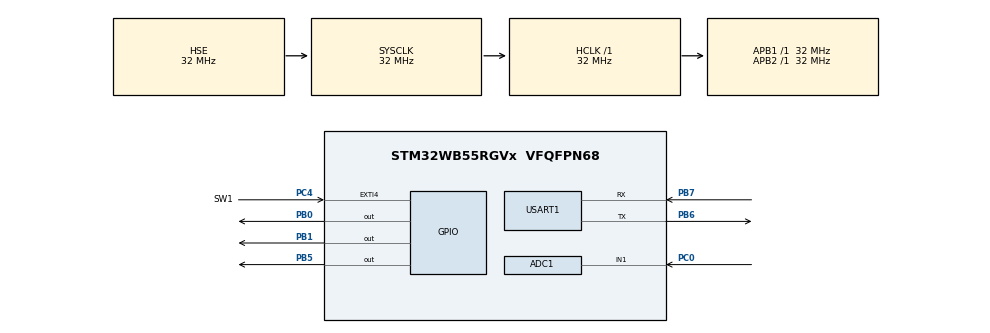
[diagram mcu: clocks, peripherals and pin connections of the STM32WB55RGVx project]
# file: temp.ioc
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Mcu.Family=STM32WB
STM32_WPAN.GAP_PERIPHERAL_ROLE=1
RCC.CortexFreq_Value=32000000
STM32_WPAN.SERVICE2_UUID_TYPE=0x01
STM32_WPAN.SERVICE1_CHAR1_GATT_NOTIFY_ATTRIBUTE_WRITE=\ 
RF1.Signal=RF_RF1
Dma.USART1_TX.0.RequestNumber=1
STM32_WPAN.SERVICE2_TYPE=PRIMARY_SERVICE
Dma.USART1_TX.0.SignalID=NONE
STM32_WPAN.CUSTOM_TEMPLATE=Enabled
VP_RTC_VS_RTC_Activate.Mode=RTC_Enabled
RCC.SYSCLKSource=RCC_SYSCLKSOURCE_HSE
ProjectManager.StackSize=0x400
STM32_WPAN.AD_SERVICE_CLASS_UUID_NBR=2
STM32_WPAN.INCLUDE_AD_TYPE_16_BIT_SERV_UUID_CMPLT_LIST=1
STM32_WPAN.SERVICE2_SHORT_NAME=eserv
STM32_WPAN.SERVICE2_CHAR1_GATT_NOTIFY_WRITE_REQ_AND_WAIT_FOR_APPL_RESP=\ 
Dma.USART1_TX.0.Priority=DMA_PRIORITY_LOW
STM32_WPAN.SERVICE2_CHAR1_UUID=2A 37
STM32_WPAN.NUMBER_OF_SERVICES=2
Dma.USART1_TX.0.Direction=DMA_MEMORY_TO_PERIPH
Dma.USART1_TX.0.SyncPolarity=HAL_DMAMUX_SYNC_NO_EVENT
STM32_WPAN.SERVICE1_UUID_TYPE=0x01
STM32_WPAN.SERVICE2_CHAR1_UUID_TYPE=0x01
RCC.HCLKFreq_Value=32000000
STM32_WPAN.LOCAL_NAME=ABC123
RCC.APB2TimFreq_Value=32000000
PB6.Signal=USART1_TX
PB6.Mode=Asynchronous
OSC_OUT.Mode=HSE-External-Oscillator
STM32_WPAN.SERVICE1_CHAR1_PROP_READ=CHAR_PROP_READ
OSC_OUT.Signal=RCC_OSC_OUT
RCC.AHBFreq_Value=32000000
ADC1.Channel-0\#ChannelRegularConversion=ADC_CHANNEL_1
RCC.HSE_VALUE=32000000
RCC.RTCClockSelection=RCC_RTCCLKSOURCE_LSE
STM32_WPAN.SERVICE1_CHAR1_UUID=2A 19
STM32_WPAN.SERVICE1_UUID=18 0F
PC14-OSC32_IN.Mode=LSE-External-Oscillator
PC4.GPIO_Label=SW1
STM32_WPAN.SERVICE1_SHORT_NAME=bserv
NVIC.DMA2_Channel4_IRQn=true\:0\:0\:false\:false\:true\:false\:true
Dma.USART1_TX.0.SyncRequestNumber=1
STM32_WPAN.SERVICE2_UUID=18 0D
PB7.Signal=USART1_RX
STM32_WPAN.INCLUDE_AD_TYPE_SHORTENED_LOCAL_NAME=1
Dma.USART1_TX.0.PeriphDataAlignment=DMA_PDATAALIGN_BYTE
STM32_WPAN.SERVICE2_LONG_NAME=eeg_service
ADC1.SamplingTime-0\#ChannelRegularConversion=ADC_SAMPLETIME_2CYCLES_5
RCC.APB3Freq_Value=16000000
NVIC.HSEM_IRQn=true\:0\:0\:false\:false\:true\:false\:true
Mcu.Package=VFQFPN68
PB1.Signal=GPIO_Output
STM32_WPAN.SERVICE2_CHAR1_LONG_NAME=eeg_value
Dma.USART1_TX.0.Instance=DMA2_Channel4
VP_TINY_LPM_VS_TINY_LPM.Mode=TINY_LPM_Enabled
SH.ADCx_IN1.0=ADC1_IN1,IN1-Single-Ended
VP_HSEM_VS_HSEM.Mode=HSEM_Activate
STM32_WPAN.CFG_GAP_DEVICE_NAME=DEABrain
RCC.APB1TimFreq_Value=32000000
Dma.USART1_TX.0.EventEnable=DISABLE
STM32_WPAN.SERVICE1_CHAR1_UUID_TYPE=0x01
Dma.Request0=USART1_TX
RCC.HSI48_VALUE=48000000
RCC.PLLSAI1N=24
Dma.USART1_TX.0.SyncSignalID=NONE
PC15-OSC32_OUT.Mode=LSE-External-Oscillator
NVIC.EXTI4_IRQn=true\:0\:0\:false\:false\:true\:true\:true
STM32_WPAN.SERVICE1_TYPE=PRIMARY_SERVICE
Dma.USART1_TX.0.MemInc=DMA_MINC_ENABLE
ADC1.Rank-0\#ChannelRegularConversion=1
Dma.USART1_TX.0.PeriphInc=DMA_PINC_DISABLE
VP_STM32_WPAN_VS_BLE_HOST.Mode=STM32_WPAN_Enabled
PC4.GPIO_PuPd=GPIO_PULLUP
ADC1.OffsetNumber-0\#ChannelRegularConversion=ADC_OFFSET_NONE
STM32_WPAN.AD_SERVICE_CLASS_UUID_1_INV=[0F, 18]
PC4.Signal=GPXTI4
Dma.USART1_TX.0.Polarity=HAL_DMAMUX_REQ_GEN_RISING
STM32_WPAN.SERVICE1_CHAR1_GATT_NOTIFY_WRITE_REQ_AND_WAIT_FOR_APPL_RESP=\ 
PC0.Signal=ADCx_IN1
PC14-OSC32_IN.Signal=RCC_OSC32_IN
STM32_WPAN.SERVICE2_CHAR1_PROP_READ=CHAR_PROP_READ
STM32_WPAN.SERVICE2_CHAR1_PROP_NOTIFY=CHAR_PROP_NOTIFY
STM32_WPAN.AD_SERVICE_CLASS_UUID_2=18 0D
STM32_WPAN.AD_SERVICE_CLASS_UUID_1=18 0F
USART1.VirtualMode-Asynchronous=VM_ASYNC
STM32_WPAN.SERVICE1_CHAR1_PROP_NOTIFY=CHAR_PROP_NOTIFY
ProjectManager.TargetToolchain=STM32CubeIDE
STM32_WPAN.LOCAL_NAME_FORMATTED=,'A','B','C','1','2','3'
Dma.USART1_TX.0.SyncEnable=DISABLE
STM32_WPAN.CUSTOM_P2P_SERVER=Disabled
OSC_IN.Signal=RCC_OSC_IN
RCC.USBFreq_Value=48000000
STM32_WPAN.SERVICE2_CHAR1_SHORT_NAME=val
PC15-OSC32_OUT.Signal=RCC_OSC32_OUT
RCC.SMPSCLockSelectionVirtual=RCC_SMPSCLKSOURCE_HSE
STM32_WPAN.SERVICE1_LONG_NAME=battery_service
Dma.USART1_TX.0.Mode=DMA_NORMAL
board=custom
STM32_WPAN.SERVICE1_CHAR1_GATT_NOTIFY_READ_REQ_AND_WAIT_FOR_APPL_RESP=\ 
VP_SEQUENCER_VS_SEQUENCER.Mode=SEQUENCER_Enabled
RCC.VCOOutputFreq_Value=32000000
STM32_WPAN.SERVICE2_CHAR1_VALUE_LENGTH=2
RCC.APB2Freq_Value=32000000
STM32_WPAN.AD_SERVICE_CLASS_UUID_2_INV=[0D, 18]
STM32_WPAN.CFG_BONDING_MODE=1
RCC.ADCFreq_Value=48000000
STM32_WPAN.SERVICE2_CHAR1_GATT_NOTIFY_READ_REQ_AND_WAIT_FOR_APPL_RESP=\ 
Mcu.Name=STM32WB55RGVx
STM32_WPAN.SERVICE1_CHAR1_SHORT_NAME=bval
RCC.SYSCLKFreq_VALUE=32000000
PB5.Signal=GPIO_Output
ADC1.master=1
OSC_IN.Mode=HSE-External-Oscillator
STM32_WPAN.SERVICE1_CHAR1_VALUE_LENGTH=2
RF1.Mode=RF1_Activate
PB7.Mode=Asynchronous
Dma.USART1_TX.0.MemDataAlignment=DMA_MDATAALIGN_BYTE
ProjectManager.HeapSize=0x200
RCC.HSI_VALUE=16000000
NVIC.PriorityGroup=NVIC_PRIORITYGROUP_4
ADC1.NbrOfConversionFlag=1
STM32_WPAN.SERVICE1_CHAR1_LONG_NAME=battery_value
RCC.APB1Freq_Value=32000000
RCC.RFWKPClockSelection=RCC_RFWKPCLKSOURCE_LSE
PB0.Signal=GPIO_Output
STM32_WPAN.SERVICE2_CHAR1_GATT_NOTIFY_ATTRIBUTE_WRITE=\ 

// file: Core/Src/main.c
/* USER CODE BEGIN Header */
/**
  ******************************************************************************
  * @file           : main.c
  * @brief          : Main program body
  ******************************************************************************
  * @attention
  *
  * <h2><center>&copy; Copyright (c) 2021 STMicroelectronics.
  * All rights reserved.</center></h2>
  *
  * This software component is licensed by ST under BSD 3-Clause license,
  * the "License"; You may not use this file except in compliance with the
  * License. You may obtain a copy of the License at:
  *                        opensource.org/licenses/BSD-3-Clause
  *
  ******************************************************************************
  */
/* USER CODE END Header */
#include "main.h"

/* USER CODE BEGIN Includes */
#include "stm32_seq.h"
/* USER CODE END Includes */

ADC_HandleTypeDef hadc1;

RTC_HandleTypeDef hrtc;

UART_HandleTypeDef huart1;
DMA_HandleTypeDef hdma_usart1_tx;

void SystemClock_Config(void);
static void MX_GPIO_Init(void);
static void MX_DMA_Init(void);
static void MX_RF_Init(void);
static void MX_RTC_Init(void);
static void MX_ADC1_Init(void);
static void MX_USART1_UART_Init(void);

int main(void)
{

  /* MCU Configuration--------------------------------------------------------*/

  /* Reset of all peripherals, Initializes the Flash interface and the Systick. */
  HAL_Init();

  /* Configure the system clock */
  SystemClock_Config();

  /* Initialize all configured peripherals */
  MX_GPIO_Init();
  MX_DMA_Init();
  MX_RF_Init();
  MX_RTC_Init();
  MX_ADC1_Init();
  MX_USART1_UART_Init();
  /* USER CODE BEGIN 2 */
  uint8_t str[] = "Hello World!\r\n";
  HAL_UART_Transmit_DMA(&huart1, str, sizeof(str));

  /* USER CODE END 2 */

  /* Init code for STM32_WPAN */
  APPE_Init();
  /* Infinite loop */
  /* USER CODE BEGIN WHILE */
  while (1)
  {
	  UTIL_SEQ_Run( UTIL_SEQ_DEFAULT );
//	  HAL_GPIO_WritePin(GPIOB, GPIO_PIN_5,GPIO_PIN_SET);
//	  HAL_GPIO_TogglePin(GPIOB, GPIO_PIN_5);
//	  HAL_Delay(100);
    /* USER CODE END WHILE */

  }
}

void SystemClock_Config(void)
{
  RCC_OscInitTypeDef RCC_OscInitStruct = {0};
  RCC_ClkInitTypeDef RCC_ClkInitStruct = {0};
  RCC_PeriphCLKInitTypeDef PeriphClkInitStruct = {0};

  /** Macro to configure the PLL multiplication factor
  */
  __HAL_RCC_PLL_PLLM_CONFIG(RCC_PLLM_DIV1);
  /** Macro to configure the PLL clock source
  */
  __HAL_RCC_PLL_PLLSOURCE_CONFIG(RCC_PLLSOURCE_MSI);
  /** Configure LSE Drive Capability
  */
  HAL_PWR_EnableBkUpAccess();
  __HAL_RCC_LSEDRIVE_CONFIG(RCC_LSEDRIVE_LOW);
  /** Configure the main internal regulator output voltage
  */
  __HAL_PWR_VOLTAGESCALING_CONFIG(PWR_REGULATOR_VOLTAGE_SCALE1);
  /** Initializes the RCC Oscillators according to the specified parameters
  * in the RCC_OscInitTypeDef structure.
  */
  RCC_OscInitStruct.OscillatorType = RCC_OSCILLATORTYPE_HSI|RCC_OSCILLATORTYPE_HSE
                              |RCC_OSCILLATORTYPE_LSE|RCC_OSCILLATORTYPE_MSI;
  RCC_OscInitStruct.HSEState = RCC_HSE_ON;
  RCC_OscInitStruct.LSEState = RCC_LSE_ON;
  RCC_OscInitStruct.HSIState = RCC_HSI_ON;
  RCC_OscInitStruct.MSIState = RCC_MSI_ON;
  RCC_OscInitStruct.HSICalibrationValue = RCC_HSICALIBRATION_DEFAULT;
  RCC_OscInitStruct.MSICalibrationValue = RCC_MSICALIBRATION_DEFAULT;
  RCC_OscInitStruct.MSIClockRange = RCC_MSIRANGE_6;
  RCC_OscInitStruct.PLL.PLLState = RCC_PLL_NONE;
  if (HAL_RCC_OscConfig(&RCC_OscInitStruct) != HAL_OK)
  {
    Error_Handler();
  }
  /** Configure the SYSCLKSource, HCLK, PCLK1 and PCLK2 clocks dividers
  */
  RCC_ClkInitStruct.ClockType = RCC_CLOCKTYPE_HCLK4|RCC_CLOCKTYPE_HCLK2
                              |RCC_CLOCKTYPE_HCLK|RCC_CLOCKTYPE_SYSCLK
                              |RCC_CLOCKTYPE_PCLK1|RCC_CLOCKTYPE_PCLK2;
  RCC_ClkInitStruct.SYSCLKSource = RCC_SYSCLKSOURCE_HSE;
  RCC_ClkInitStruct.AHBCLKDivider = RCC_SYSCLK_DIV1;
  RCC_ClkInitStruct.APB1CLKDivider = RCC_HCLK_DIV1;
  RCC_ClkInitStruct.APB2CLKDivider = RCC_HCLK_DIV1;
  RCC_ClkInitStruct.AHBCLK2Divider = RCC_SYSCLK_DIV1;
  RCC_ClkInitStruct.AHBCLK4Divider = RCC_SYSCLK_DIV1;

  if (HAL_RCC_ClockConfig(&RCC_ClkInitStruct, FLASH_LATENCY_1) != HAL_OK)
  {
    Error_Handler();
  }
  /** Initializes the peripherals clocks
  */
  PeriphClkInitStruct.PeriphClockSelection = RCC_PERIPHCLK_SMPS|RCC_PERIPHCLK_RFWAKEUP
                              |RCC_PERIPHCLK_RTC|RCC_PERIPHCLK_USART1
                              |RCC_PERIPHCLK_ADC;
  PeriphClkInitStruct.PLLSAI1.PLLN = 24;
  PeriphClkInitStruct.PLLSAI1.PLLP = RCC_PLLP_DIV2;
  PeriphClkInitStruct.PLLSAI1.PLLQ = RCC_PLLQ_DIV2;
  PeriphClkInitStruct.PLLSAI1.PLLR = RCC_PLLR_DIV2;
  PeriphClkInitStruct.PLLSAI1.PLLSAI1ClockOut = RCC_PLLSAI1_ADCCLK;
  PeriphClkInitStruct.Usart1ClockSelection = RCC_USART1CLKSOURCE_PCLK2;
  PeriphClkInitStruct.AdcClockSelection = RCC_ADCCLKSOURCE_PLLSAI1;
  PeriphClkInitStruct.RTCClockSelection = RCC_RTCCLKSOURCE_LSE;
  PeriphClkInitStruct.RFWakeUpClockSelection = RCC_RFWKPCLKSOURCE_LSE;
  PeriphClkInitStruct.SmpsClockSelection = RCC_SMPSCLKSOURCE_HSE;
  PeriphClkInitStruct.SmpsDivSelection = RCC_SMPSCLKDIV_RANGE0;
  if (HAL_RCCEx_PeriphCLKConfig(&PeriphClkInitStruct) != HAL_OK)
  {
    Error_Handler();
  }
}

static void MX_ADC1_Init(void)
{

  ADC_ChannelConfTypeDef sConfig = {0};

  /** Common config
  */
  hadc1.Instance = ADC1;
  hadc1.Init.ClockPrescaler = ADC_CLOCK_ASYNC_DIV1;
  hadc1.Init.Resolution = ADC_RESOLUTION_12B;
  hadc1.Init.DataAlign = ADC_DATAALIGN_RIGHT;
  hadc1.Init.ScanConvMode = ADC_SCAN_DISABLE;
  hadc1.Init.EOCSelection = ADC_EOC_SINGLE_CONV;
  hadc1.Init.LowPowerAutoWait = DISABLE;
  hadc1.Init.ContinuousConvMode = DISABLE;
  hadc1.Init.NbrOfConversion = 1;
  hadc1.Init.DiscontinuousConvMode = DISABLE;
  hadc1.Init.ExternalTrigConv = ADC_SOFTWARE_START;
  hadc1.Init.ExternalTrigConvEdge = ADC_EXTERNALTRIGCONVEDGE_NONE;
  hadc1.Init.DMAContinuousRequests = DISABLE;
  hadc1.Init.Overrun = ADC_OVR_DATA_PRESERVED;
  hadc1.Init.OversamplingMode = DISABLE;
  if (HAL_ADC_Init(&hadc1) != HAL_OK)
  {
    Error_Handler();
  }
  /** Configure Regular Channel
  */
  sConfig.Channel = ADC_CHANNEL_1;
  sConfig.Rank = ADC_REGULAR_RANK_1;
  sConfig.SamplingTime = ADC_SAMPLETIME_2CYCLES_5;
  sConfig.SingleDiff = ADC_SINGLE_ENDED;
  sConfig.OffsetNumber = ADC_OFFSET_NONE;
  sConfig.Offset = 0;
  if (HAL_ADC_ConfigChannel(&hadc1, &sConfig) != HAL_OK)
  {
    Error_Handler();
  }

}

static void MX_RF_Init(void)
{

}

static void MX_RTC_Init(void)
{

  /** Initialize RTC Only
  */
  hrtc.Instance = RTC;
  hrtc.Init.HourFormat = RTC_HOURFORMAT_24;
  hrtc.Init.AsynchPrediv = CFG_RTC_ASYNCH_PRESCALER;
  hrtc.Init.SynchPrediv = CFG_RTC_SYNCH_PRESCALER;
  hrtc.Init.OutPut = RTC_OUTPUT_DISABLE;
  hrtc.Init.OutPutPolarity = RTC_OUTPUT_POLARITY_HIGH;
  hrtc.Init.OutPutType = RTC_OUTPUT_TYPE_OPENDRAIN;
  hrtc.Init.OutPutRemap = RTC_OUTPUT_REMAP_NONE;
  if (HAL_RTC_Init(&hrtc) != HAL_OK)
  {
    Error_Handler();
  }

}

static void MX_USART1_UART_Init(void)
{

  huart1.Instance = USART1;
  huart1.Init.BaudRate = 115200;
  huart1.Init.WordLength = UART_WORDLENGTH_8B;
  huart1.Init.StopBits = UART_STOPBITS_1;
  huart1.Init.Parity = UART_PARITY_NONE;
  huart1.Init.Mode = UART_MODE_TX_RX;
  huart1.Init.HwFlowCtl = UART_HWCONTROL_NONE;
  huart1.Init.OverSampling = UART_OVERSAMPLING_16;
  huart1.Init.OneBitSampling = UART_ONE_BIT_SAMPLE_DISABLE;
  huart1.Init.ClockPrescaler = UART_PRESCALER_DIV1;
  huart1.AdvancedInit.AdvFeatureInit = UART_ADVFEATURE_NO_INIT;
  if (HAL_UART_Init(&huart1) != HAL_OK)
  {
    Error_Handler();
  }
  if (HAL_UARTEx_SetTxFifoThreshold(&huart1, UART_TXFIFO_THRESHOLD_1_8) != HAL_OK)
  {
    Error_Handler();
  }
  if (HAL_UARTEx_SetRxFifoThreshold(&huart1, UART_RXFIFO_THRESHOLD_1_8) != HAL_OK)
  {
    Error_Handler();
  }
  if (HAL_UARTEx_DisableFifoMode(&huart1) != HAL_OK)
  {
    Error_Handler();
  }

}

static void MX_DMA_Init(void)
{

  /* DMA controller clock enable */
  __HAL_RCC_DMAMUX1_CLK_ENABLE();
  __HAL_RCC_DMA2_CLK_ENABLE();

  /* DMA interrupt init */
  /* DMA2_Channel4_IRQn interrupt configuration */
  HAL_NVIC_SetPriority(DMA2_Channel4_IRQn, 0, 0);
  HAL_NVIC_EnableIRQ(DMA2_Channel4_IRQn);

}

static void MX_GPIO_Init(void)
{
  GPIO_InitTypeDef GPIO_InitStruct = {0};

  /* GPIO Ports Clock Enable */
  __HAL_RCC_GPIOC_CLK_ENABLE();
  __HAL_RCC_GPIOB_CLK_ENABLE();

  /*Configure GPIO pin Output Level */
  HAL_GPIO_WritePin(GPIOB, GPIO_PIN_0|GPIO_PIN_1|GPIO_PIN_5, GPIO_PIN_RESET);

  /*Configure GPIO pin : SW1_Pin */
  GPIO_InitStruct.Pin = SW1_Pin;
  GPIO_InitStruct.Mode = GPIO_MODE_IT_RISING;
  GPIO_InitStruct.Pull = GPIO_PULLUP;
  HAL_GPIO_Init(SW1_GPIO_Port, &GPIO_InitStruct);

  /*Configure GPIO pins : PB0 PB1 PB5 */
  GPIO_InitStruct.Pin = GPIO_PIN_0|GPIO_PIN_1|GPIO_PIN_5;
  GPIO_InitStruct.Mode = GPIO_MODE_OUTPUT_PP;
  GPIO_InitStruct.Pull = GPIO_NOPULL;
  GPIO_InitStruct.Speed = GPIO_SPEED_FREQ_LOW;
  HAL_GPIO_Init(GPIOB, &GPIO_InitStruct);

  /* EXTI interrupt init*/
  HAL_NVIC_SetPriority(EXTI4_IRQn, 0, 0);
  HAL_NVIC_EnableIRQ(EXTI4_IRQn);

}

void Error_Handler(void)
{
  __disable_irq();
  while (1)
  {
  }
}

/************************ (C) COPYRIGHT STMicroelectronics *****END OF FILE****/
